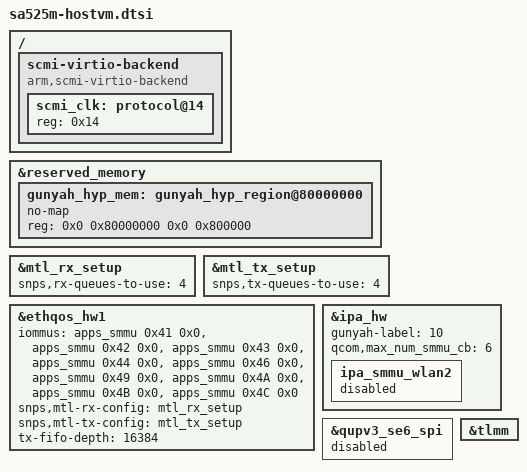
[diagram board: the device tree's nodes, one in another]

&reserved_memory {
	gunyah_hyp_mem: gunyah_hyp_region@80000000 {
		no-map;
		reg = <0x0 0x80000000 0x0 0x800000>;
	};
};

&mtl_rx_setup {
	snps,rx-queues-to-use = <4>;
};

&mtl_tx_setup {
	snps,tx-queues-to-use = <4>;
};

&ethqos_hw1 {
	iommus = <&apps_smmu 0x41 0x0>,
		 <&apps_smmu 0x42 0x0>,
		 <&apps_smmu 0x43 0x0>,
		 <&apps_smmu 0x44 0x0>,
		 <&apps_smmu 0x46 0x0>,
		 <&apps_smmu 0x49 0x0>,
		 <&apps_smmu 0x4A 0x0>,
		 <&apps_smmu 0x4B 0x0>,
		 <&apps_smmu 0x4C 0x0>;
		snps,mtl-rx-config = <&mtl_rx_setup>;
		snps,mtl-tx-config = <&mtl_tx_setup>;

		tx-fifo-depth = <16384>;

};

&ipa_hw {
	gunyah-label = <10>;
	qcom,max_num_smmu_cb = <6>;

	/* Disable wlan2 on PVM for GVM v2x smmu cb to use peripheral 3 */
	ipa_smmu_wlan2 {
		status = "disabled";
	};
};

/ {
	scmi-virtio-backend {
		compatible = "arm,scmi-virtio-backend";
		#address-cells = <1>;
		#size-cells = <0>;

		scmi_clk: protocol@14 {
			reg = <0x14>;
		};
	};
};

&qupv3_se6_spi {
	status = "disabled";
};

&tlmm {
	/delete-node/ hsm-rst-hog;
};
